# moonlight_application register map
Vendor: Nordic Semiconductor; Series: lumos; File version: 1
CPU: CM33 r0p4, little endian, MPU, FPU, 3 interrupt priority bits, 176 interrupts, 4 SAU regions
Registers are 32-bit, read-write, reset 0x0 unless marked. A register's access mark holds for its fields unless they carry their own. Offsets are from the block's base; [hi:lo] are bit positions; lines under a group give offsets from that group; 'fields as' and 'values as' point back to an identical list.

## GLOBAL_OSCILLATORS_NS — Oscillator control 0
Base 0x40120000
Same registers: GLOBAL_OSCILLATORS_S 0x50120000
0x700 XOSC32M group — 32 MHz oscillator control
  0x00 STATUS ro — Oscillator status
    [12:9] IDACFSMSTATE — Current IDAC Regulation State
      0=IDLE Mode; 1=ListenPkd (Listening for any changes on peak detector Mode); 2=WaitPkd (Waiting for peak detector to update Mode); 4=CodeIncrement (Incrementing IDAC Code Mode); 8=CodeDecrement (Decrementing IDAC Code Mode)
    [8:0] MAINFSMSTATE — Current Oscillator State
      6=Power Down Mode; 231=Standby Mode; 121=Pierce Mode; 0x139=ExtSin (External Sine Mode); 0x1AD=ExtSqrSin192M (External Square or Sine 192MHz Mode); 39=Power Up Mode; 37=PllCkStart (Pll Clock Started Mode); 45=PllCkRunningWaitCkRadio (Pll Clock Running And Waiting For Radio Clock Mode); 109=RadioCkStartWaitIdacRegulation (Radio Clock Started, Waiting For IDAC Regulation Mode); 105=RadioCkRunning (Radio Clock Running Mode); 0x127=PowerUpExtSin (Power Up to Sine External Mode); 0x1A7=PowerUpExtSqrSin192M (Power Up to Sine 192M, Square External Mode); 97=StandbyNoQuality (Standby With Both Clocks Started Mode); 103=StandbyClockMute (Standby to Start Both Clocks Mode); 0x1A5=ExtSqrSin192MNoQuality (External Sine 192M, Square With No Quality Signals Mode); 0x187=ExtSqrSin192MMute (External Sine 192M, Square With No Clocks Running Mode); 0x121=ExtSinNoQual (External Sine With No Quality Signals Mode); 0x107=ExtSinMute (External Sine With No Clocks Running Mode)
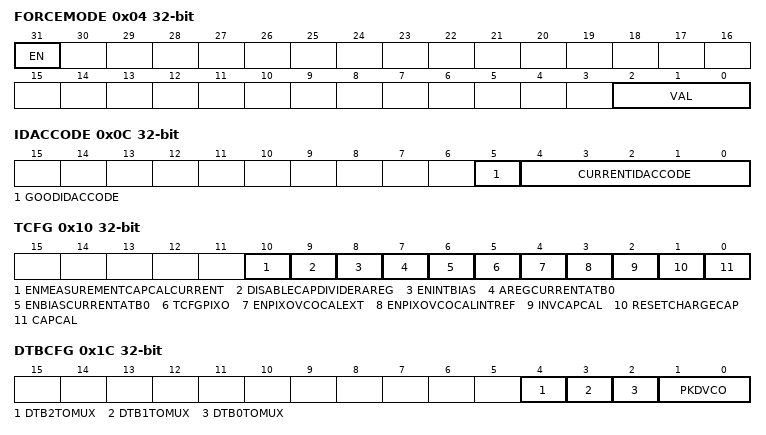
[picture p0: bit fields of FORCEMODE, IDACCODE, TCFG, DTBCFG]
  0x04 FORCEMODE — Force Xosc32M crystal into a certain mode
    [31] EN — Enable force mode for the XOSC32M
      0=Disabled (Disable force mode for FSM); 1=Enabled (Enable force mode for FSM)
    [2:0] VAL — Current Xosc32M mode
      0=PowerDown (Force to Power Down Mode); 1=Standby (Force to Standby mode); 2=Pierce (Force to Pierce mode); 3=ExtSqrSin192M (Force to External Square or External Sine 192MHz mode); 4=ExtSin (Force to External Sine mode)
  0x08 PEAKDETECTOR ro — Peak Detector pkdOut
    [2:0] PEAKDETECTOR — Current Peak Detector pkdOut
  0x0C IDACCODE ro — IDAC Regulation Code
    [5] GOODIDACCODE — The IDAC Regulation Took Place, and the Current IDAC Code is a Good Code
    [4:0] CURRENTIDACCODE — Current IDAC Regulation Code
  0x10 CLOCKQUALITY ro — Clock quality indicator
    [1:0] INDICATOR
      0=NoClockAvailable (XOSC32M does not output a clock); 1=PllQuality (XOSC32M outputs a clock that is used by PLL); 3=RadioQuality (XOSC32M has sufficient accuracy and the HFCLK controller has enabled the 32 MHz RADIO clock XOCLK32M)
  0x14 CONFIG group — Unspecified
    0x00 INJECTMODEENABLE — Enable injection mode for kickstarting the oscillator
      [0] VAL — Enable injection mode
        0=Disabled (Disable injection mode); 1=Enabled (Enable injection mode)
    0x04 FSMFREEZE — Freeze the FSM in the current mode (no inputs will change the FSM and this is used when requesting PIXO mode)
      [0] VAL — Enable FSM freeze
        0=Disabled (Disable FSM freeze); 1=Enabled (Enable FSM freeze)
    0x08 INTCAP reset 0x24 — Crystal load capacitor as seen by the crystal across its terminals, including pin capacitance but excluding PCB stray capacitance.
      [5:0] VAL
    0x0C UPDATEIDACCODE wo — Update IDAC code from APB (IDAC register).
      [0] UPDATE
        1=Trigger task
    0x10 TCFG — Test configuration bits
      [10] ENMEASUREMENTCAPCALCURRENT — Enable or disable measurement of 2 uA CAP_CAL current
        0=Disable measurement of 2 uA CAP_CAL current; 1=Enable measurement of 2 uA CAP_CAL current
      [9] DISABLECAPDIVIDERAREG — Enable or disable capacitive divider at AREG input when going to Pierce mode. This functionality will reduce start-up times in Pierce mode
        0=Enable capacitive divider at AREG; 1=Disable capacitive divider at AREG
      [8] ENINTBIAS — TCFG bit to enable bias (bias is normally only enabled when Pierce, SIN2SQR or PKD is enabled. This bit gives additional control of bias)
        0=Disable internal bias enabling; 1=Enable internal bias enabling
      [7] AREGCURRENTATB0 — Enable copy of AREG current to ATB0 (scaled down by x25)
        0=Disable copy of AREG current to ATB0; 1=Enable copy of AREG current to ATB0
      [6] ENBIASCURRENTATB0 — Enable 8 uA biasing current to ATB0 from internal biasing module
        0=Disable 8 uA biasing current; 1=Enable 8 uA biasing current
      [5] TCFGPIXO — Reserved or Spare TCFG Bit For PIXO
      [4] ENPIXOVCOCALEXT — Enable PIXO VCO Calibration Comparator From External Reference Voltage
        0=Disable PIXO VCO calibration comparator; 1=Enable PIXO VCO calibration comparator
      [3] ENPIXOVCOCALINTREF — Enable or disable PIXO VCO calibration comparator with internal reference voltage (resistive divider from VDD_ANA_0V9)
        values as ENPIXOVCOCALEXT
      [2] INVCAPCAL — Invert capacitor calibration comparator output
        0=No invert for capacitor calibration comparator output; 1=Invert capacitor calibration comparator output
      [1] RESETCHARGECAP — Reset charge on capacitor within capacitor calibration module
        0=Disable reset charge; 1=Enable (Reset charge on capacitor)
      [0] CAPCAL — Enable or disable capacitor calibration module
        0=Disable capacitor calibration module; 1=Enable capacitor calibration module
    0x14 ATB0CFG — Analog testbus 0 configuration
      [3:0] ATB0CFG
        0=HiZ0 (Allow other IPs to use ATB0); 1=HiZ1 (Allow other IPs to use ATB0); 7=HiZ2 (Allow other IPs to use ATB0); 8=IbppAtb8u (8 uA bias generator test current); 9=VcoCalCmp (Force external reference voltage to PIXO VCO calibration comparator (instead of using internal reference). This gives possibility to compare VCTRL of PIXO VCO with externally applied voltage); 10=IbppCapCal2u (2 uA current used for capacitor calibration); 11=IbppAregCpy (Copy of AREG current (divided down by x25))
    0x18 ATB1CFG — Analog testbus 1 configuration
      [3:0] ATB1CFG
        7=HiZ (Allow other IPs to use ATB1); 8=VddInt3V0 (Measure internal 3V0 voltage on ATB1); 11=Xosc32MPierce (Pierce clock on ATB1 for PN measurement in lab. Keep capacitance on ATB1 as low as possible for this measurement (maximum 30 pF)); 12=Xosc32MPixo (PIXO clock on ATB1 for PN measurement in lab. Keep capacitance on ATB1 as low as possible for this measurement (maximum 30 pF))
    0x1C DTBCFG — Digital Test Bus configuration
      [4] DTB2TOMUX — Connect DTB2 to internal MUX
      [3] DTB1TOMUX — Connect DTB1 to internal MUX
      [2] DTB0TOMUX — Connect DTB0 to internal MUX
      [1:0] PKDVCO
        0=Pkd123 (Monitoring of amplitude regulation process); 1=Xosc32MReady (Divided version of version of output clock and READY. Clock is divided down to 4 MHz internally); 2=PixoVcoComp (Output from PIXO VCO calibration comparator and output from capacitor calibration comparator); 3=READY, PKD_1 and PKD_2 on DTB makes it easier to measure start-up time in the lab since edge of READY can be used as reference start-point, while PKD outputs can be used as reference stop-points
  0x34 CALIBRATION group — Unspecified
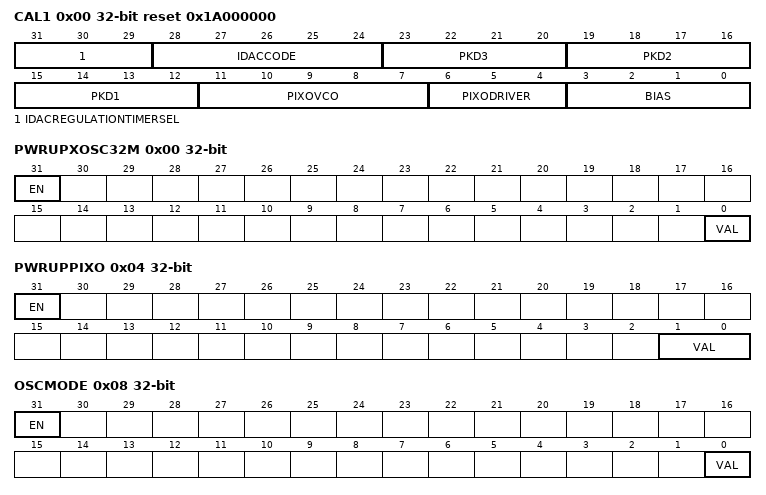
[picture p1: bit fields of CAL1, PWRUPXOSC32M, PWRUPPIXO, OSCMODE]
    0x00 CAL1 reset 0x1A000000 — Calibration registers written from FICR
      [31:29] IDACREGULATIONTIMERSEL — Configure the IDAC regulation time constant 256*(1 + n) us
      [28:24] IDACCODE — IDAC Configuration Value
      [23:20] PKD3 — Second complement trim bus for third peak detector
      [19:16] PKD2 — Second complement trim bus for second peak detector
      [15:12] PKD1 — Second complement trim bus for first peak detector
      [11:7] PIXOVCO — Second complement trim bus for PIXO VCO
      [6:4] PIXODRIVER — Second complement trim bus for PIXO drive strength
      [3:0] BIAS — Second complement trim bus for bias generator
  0x38 OVERRIDE group — Unspecified
    0x00 PWRUPXOSC32M — Override the PWRUP_XOSC32M signal in the analog module
      [31] EN — Enable the override
        0=Disabled (Override is disabled); 1=Enabled (Override is enabled)
      [0] VAL — Override value
    0x04 PWRUPPIXO — Override the XOSC32M_PIXO_PWRUP signal in the analog module
      [31] EN — Enable the override
        values as XOSC32M.OVERRIDE.PWRUPXOSC32M.EN
      [1:0] VAL — Override value
    0x08 OSCMODE — Override the XOSC32M_OSC_MODE signal in the analog module
      [31] EN — Enable the override
        values as XOSC32M.OVERRIDE.PWRUPXOSC32M.EN
      [0] VAL — Override value for the signal
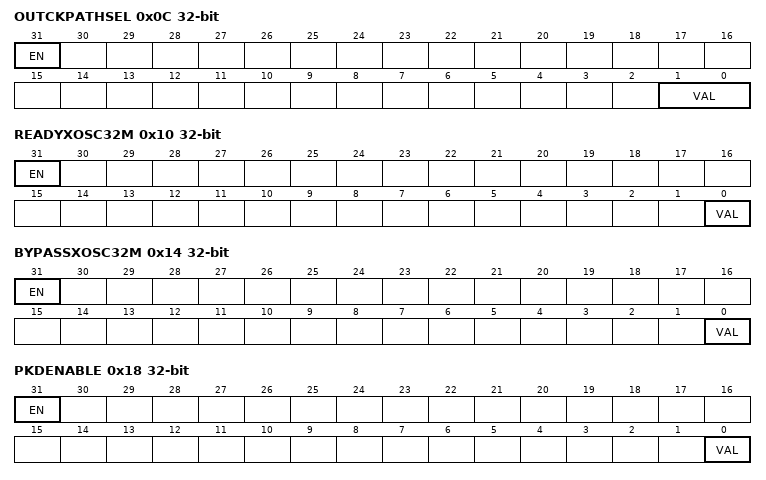
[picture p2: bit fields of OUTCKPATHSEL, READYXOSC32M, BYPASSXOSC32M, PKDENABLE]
    0x0C OUTCKPATHSEL — Override XOSC32M_OUTSEL signal in the analog module. 00: Sin-to-square output path (Pierce, ext-sin modes) 01: PIXO output path (PIXO mode) 10: Schmitt trigger output path (ext-sq mode) 11: Do not use
      [31] EN — Enable the override
        values as XOSC32M.OVERRIDE.PWRUPXOSC32M.EN
      [1:0] VAL — Override value for the signal
    0x10 READYXOSC32M — Override the READY_XOSC32M signal from analog module
      fields as XOSC32M.OVERRIDE.OSCMODE
    0x14 BYPASSXOSC32M — Override the XOSC32M_OSC_BYPASS signal in the analog module
      fields as XOSC32M.OVERRIDE.OSCMODE
    0x18 PKDENABLE — Override the XOSC32M_PKD_EN signal in the analog module
      fields as XOSC32M.OVERRIDE.OSCMODE
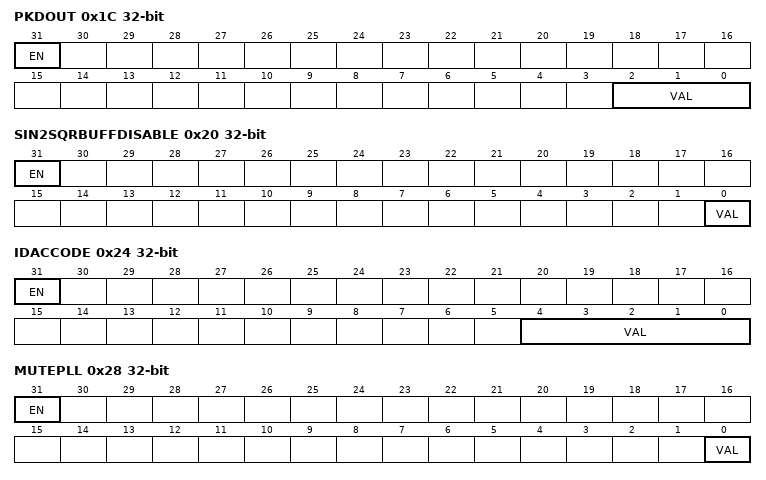
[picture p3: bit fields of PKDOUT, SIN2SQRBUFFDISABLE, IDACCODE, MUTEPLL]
    0x1C PKDOUT — Override the XOSC32M_PKD_OUT signal from analog module
      [31] EN — Enable the override
        values as XOSC32M.OVERRIDE.PWRUPXOSC32M.EN
      [2:0] VAL — Override value for the signal
    0x20 SIN2SQRBUFFDISABLE — Override the XOSC32M_SIN2SQR_DISABLE signal in the analog module
      fields as XOSC32M.OVERRIDE.OSCMODE
    0x24 IDACCODE — Override the XOSC32M_IDAC code in the analog module
      [31] EN — Enable the override
        values as XOSC32M.OVERRIDE.PWRUPXOSC32M.EN
      [4:0] VAL — Override value for the signal
    0x28 MUTEPLL — Override the XOSC32M_MUTE_PLL signal in the analog module
      [31] EN — Enable the override
        values as XOSC32M.OVERRIDE.PWRUPXOSC32M.EN
      [0] VAL — Override value of the signal
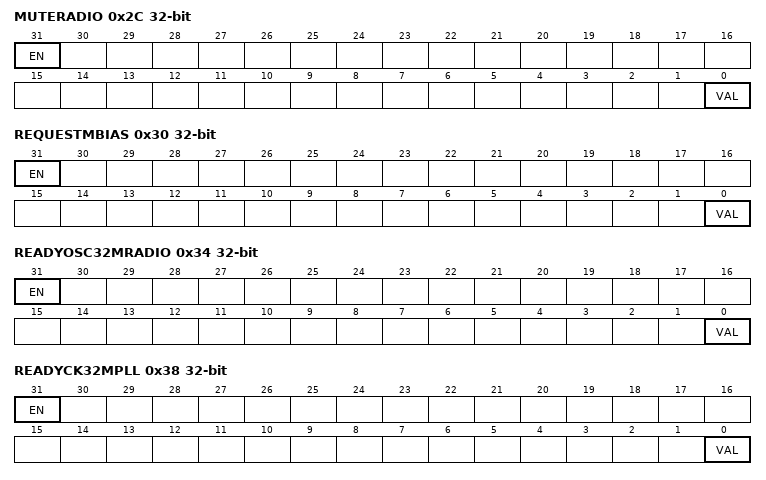
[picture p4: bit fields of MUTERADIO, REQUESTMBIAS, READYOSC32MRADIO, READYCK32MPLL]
    0x2C MUTERADIO — Override the XOSC32M_MUTE_RADIO signals in the analog module
      fields as XOSC32M.OVERRIDE.MUTEPLL
    0x30 REQUESTMBIAS — Override the requestMbias_a signal from the MMI
      fields as XOSC32M.OVERRIDE.MUTEPLL
    0x34 READYOSC32MRADIO — Override the readyOsc32M_Radio signals from the MMI
      fields as XOSC32M.OVERRIDE.MUTEPLL
    0x38 READYCK32MPLL — Override the readyCk32M_Pll signal from the MMI
      fields as XOSC32M.OVERRIDE.MUTEPLL
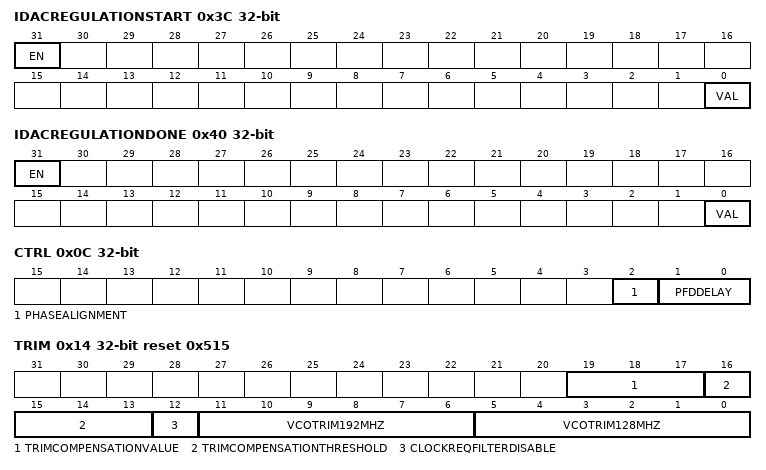
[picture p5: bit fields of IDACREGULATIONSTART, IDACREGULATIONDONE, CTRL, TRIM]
    0x3C IDACREGULATIONSTART — Override the idacRegulationStart signal from the main FSM
      fields as XOSC32M.OVERRIDE.MUTEPLL
    0x40 IDACREGULATIONDONE — Override the idacRegulationDone signal from the IDAC regulation FSM
      fields as XOSC32M.OVERRIDE.MUTEPLL
0x800 PLL group — Oscillator control
  0x00 FREQ reset 0x3 — CPU frequency
    [1:0] FREQ — Select CPU speed
      0=CK192M (192 MHz); 1=CK128M (128 MHz); 2=CK96M (96 MHz); 3=CK64M (64 MHz)
  0x04 CURRENTFREQ ro reset 0x3 — Current CPU frequency
    [1:0] CURRENTFREQ — Active CPU speed
      values as PLL.FREQ.FREQ
  0x10 CONFIG group — Unspecified
    0x00 ATB0CFG — Analog testbus configuration
      [1:0] ATB0CFG — Loop filter voltage and OSC_PLL_VHF_0V9
        0=Disabled; 1=VTUNE (Observe/force tune voltage VTUNE on ATB0); 2=OSC (Observe OSC_PLL_VHF_0V9 on ATB0)
    0x04 PROGCHPUMP — Program charge pump current
      [0] PROGCHPUMP
        0=I4uA (4 uA); 1=I8uA (8 uA)
    0x08 MUTE — Disable clock output
      [0] MUTE
        0=NotMuted (Clock is output); 1=Muted (Clock is not output)
    0x0C CTRL — PLL control register
      [2] PHASEALIGNMENT — Disables phase alignment at startup, and enables PFD in calibration mode
      [1:0] PFDDELAY — Adjust internal PFD delay / CP minimum UP/DN pulse length
        0=P0 (Minimum delay); 1=P50 (+50 ps delay); 2=P100 (+100 ps delay); 3=P150 (+150 ps delay)
    0x10 TEST — Unspecified
      [5:0] TEST — PLL_TEST_0V9[5]: Override hardcoded bias setup for VCO. PLL_TEST_0V9[4:3]: KVCO controlling bias. PLL_TEST_0V9[2:0]: constant current controlling bias.
    0x14 TRIM reset 0x515 — VCO trim values for the 192 MHz PLL
      [19:17] TRIMCOMPENSATIONVALUE — Trim compensation when deviation larger than TRIMCOMPENSATIONTHRESHOLD is detected.
        0=Disabled (Trim compensation disabled); 1=T1 (Compensate with 1 trim step (~1.5 percent)); 7=T7 (Compensate with 7 trim step (~10.5 percent))
      [16:13] TRIMCOMPENSATIONTHRESHOLD — Threshold for enabling trim compenastion. Trim compensation actived when measured cycles are below the threshold.
        0=T132 (Threshold at 132 cycles (~0.75 percent)); 1=T131 (Threshold at 131 cycles (~1.5 percent)); 15=T117 (Threshold at 117 cycles (~12 percent))
      [12] CLOCKREQFILTERDISABLE — Disable clock request filter
        0=Enable clock request filter; 1=Disable clock request filter
      [11:6] VCOTRIM192MHZ — Trim value for the PLL VCO at 192 MHz
      [5:0] VCOTRIM128MHZ — Trim value for the PLL VCO at 128 MHz
  0x30 DBG group — Unspecified
    0x00 STATUS ro — Current state of the MMIs state machine
      [7:0] STATE — Current state of the MMI state machine
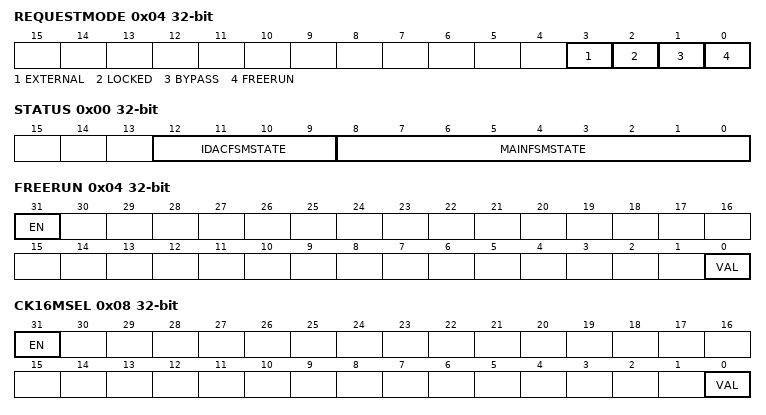
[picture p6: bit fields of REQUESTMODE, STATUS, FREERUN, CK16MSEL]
    0x04 REQUESTMODE — Backdoor to request PLL mode
      [3] EXTERNAL — Request external mode
        0=Disabled (No request); 1=Request external mode
      [2] LOCKED — Request locked mode
        0=Disabled (No request); 1=Request locked mode
      [1] BYPASS — Request bypass mode
        0=Disabled (No request); 1=Request bypass mode
      [0] FREERUN — Request free running mode
        0=Disabled (No request); 1=Request free running mode
  0x40 FREQMETER group — Unspecified
    0x00 STATUS ro — Status of frequency meter
      [16] STATUS — Status of frequency meter
        0=Idle (Frequency meter idle.); 1=Ongoing (Frequency measurement ongoing.)
      [10:0] RESULT — Result from last frequency measurement (HF cycles).
    0x04 START wo — Start a new frequency measurement.
      [0] START — Input clock for calibration engine.
        1=Trigger task
    0x08 CONFIG — Frequency meter config
      [0] MODE — Sets frequency meter mode.
        0=Locktuning (Target 132 HF cycles.); 1=Calibration (Measure for 8 us.)
  0x50 CAL group — Unspecified
    0x00 ENABLE — Enable ring oscillator calibration
      [0] CALENABLE
        0=Disable (Normal operation); 1=Enabled (Calibration mode)
    0x04 CLK — Input clock for calibration engine. Not used in normal operation
      [0] CALCLK — Input clock for calibration engine
    0x08 CMP ro — Ring oscillator calibration comparator output
      [0] CALCMP
  0x60 OVERRIDE group — Unspecified
    0x00 PWRUP — Override PWRUP
      [31] EN — Enable override
        values as XOSC32M.OVERRIDE.PWRUPXOSC32M.EN
      [0] VAL — Override value
    0x04 FREERUN — Override FREERUN
      fields as PLL.OVERRIDE.PWRUP
    0x08 CK16MSEL — Override CK16M_SEL
      [31] EN — Enable override
        values as XOSC32M.OVERRIDE.PWRUPXOSC32M.EN
      [0] VAL — Override value
        0=Bypass 32M outputs from reference; 1=Normal (32M generated internally)
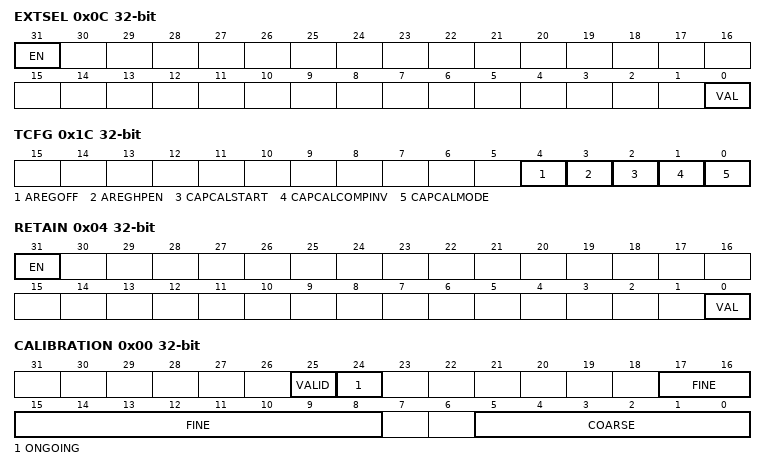
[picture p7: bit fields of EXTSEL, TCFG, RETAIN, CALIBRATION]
    0x0C EXTSEL — Override EXT_SEL
      [31] EN — Enable override
        values as XOSC32M.OVERRIDE.PWRUPXOSC32M.EN
      [0] VAL — Override value
        0=Normal operation; 1=External (Reference clock bypassed to VCO output. Internal dividers functional)
    0x10 FREQ — Override frequency handler. Value directly from FREQ register
      [31] EN — Enable override
        values as XOSC32M.OVERRIDE.PWRUPXOSC32M.EN
0x900 XOSC32KI group — 32 kHz oscillator control
  0x00 BYPASS — Enable or disable bypass of LFCLK crystal oscillator with external clock source
    [0] BYPASS
      0=Disabled (Disable (use with crystal or low-swing external source)); 1=Enabled (Enable (use with rail-to-rail external source))
  0x04 INTCAP — Programmable capacitance of XC1 and XC2
    [5:0] VAL — Crystal load capacitor as seen by the crystal across its terminals, including pin capacitance but excluding PCB stray capacitance.
  0x08 TRIM — Trim values
    [4] EXTBIAS — Control the use of external bias current
      0=Disabled (Internal bias current is used); 1=Enabled (External bias current is used)
    [3:0] CONSTCURRTRIM — Constant current level trim. 0 - 90 nA in 6 nA step size (typical)
  0x0C MUTE — Disable clock output
    [0] MUTE
      0=NotMuted (Clock output on OSC_32K_0V9); 1=Muted (Clock is muted. OSC_32K_0V9 is zero.)
  0x10 PDCORE — Power down crystal driver
    [0] POWERDOWN
      0=PowerUp (Pierce cell, amplitude regulator, and IDAC are powered.); 1=PowerDown (Pierce cell, amplitude regulator, and IDAC are powered down.)
  0x14 ATBCFG — Analog testbus configuration
    [1:0] ATBCFG — Analog testbus control
      0=Disabled; 2=IntBias (Internal bias to ATB0)
  0x18 DTBCFG — Digital testbus configuration
    [1:0] DTBCFG — Digital testbus control
      0=Vss; 2=CmpCapCal
  0x1C TCFG — Test configuration bus
    [4] AREGOFF — AREG off, only constant current source driving xtal
      0=AregOn (Unspecified); 1=AregOff (Unspecified)
    [3] AREGHPEN — Enable AREG_HP mode, 2x current in AREG
      0=Disabled (Unspecified); 1=Enabled (Unspecified)
    [2] CAPCALSTART — Start CAPCAL measurement
      0=DoNotStart (Unspecified); 1=Start (Unspecified)
    [1] CAPCALCOMPINV — Invert CAPCAL comparators
      0=NotInverted (Unspecified); 1=Inverted (Unspecified)
    [0] CAPCALMODE — CAPCAL mode enable
      0=Disabled (Unspecified); 1=Enabled (Unspecified)
  0x20 OVERRIDE group — Unspecified
    0x00 PWRUP — Override PWRUP
      fields as PLL.OVERRIDE.PWRUP
    0x04 RETAIN — Override RETAIN
      fields as PLL.OVERRIDE.PWRUP
0xA00 RCOSC32K group — 32.768 kHz RC oscillator
  0x00 CALIBRATION ro — Calibration status
    [25] VALID — Calibration has been completed
      0=NoValid (Calibration is not ongoing); 1=Calid (Calibration is ongoing)
    [24] ONGOING — Calibration is ongoing
      0=Idle (Calibration is not ongoing); 1=Ongoing (Calibration is ongoing)
    [17:8] FINE — Fine calibration value
    [5:0] COARSE — Coarse calibration value
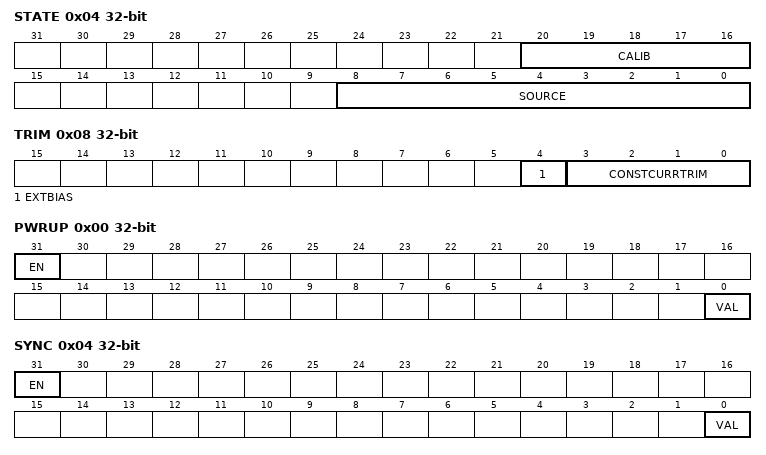
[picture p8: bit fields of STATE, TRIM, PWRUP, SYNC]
  0x04 STATE ro — FSM states
    [20:16] CALIB — Calibration engine state
      0=RESET (Unspecified); 1=SETTLING (Unspecified); 2=INIT_MEAS_FAST (Unspecified); 3=MEAS_FAST (Unspecified); 4=INIT_MEAS_SLOW (Unspecified); 5=MEAS_SLOW (Unspecified); 22=PROG_COARSE (Unspecified); 15=PROG_FINE (Unspecified); 24=IDLE (Unspecified)
    [8:0] SOURCE — Source controller FSM state
      91=STANDBY (Unspecified); 31=ENABLE_DEBOUNCER (Unspecified); 15=START_XOSC (Unspecified); 0x123=START_CALIB (Unspecified); 133=CALIB (Unspecified); 39=SYNC_RCOSC (Unspecified); 13=SWITCH_OSC (Unspecified); 11=STOP_XOSC (Unspecified); 27=NORMAL_MODE (Unspecified); 38=SYNC_RCOSC_PWR_DOWN (Unspecified); 12=SWITCH_OSC_PWR_DOWN (Unspecified); 10=STOP_XOSC_PWR_DOWN (Unspecified); 25=STOP_RCOSC_PWR_DOWN (Unspecified)
  0x08 TRIM — RCOSC coarse calibration input This value is read from FICR
    [7:2] TRIMCOARSEIN — RCOSC coarse calibration input
    [1:0] CALLENGTH — 32kHz RC oscillator calibration length in number of cycles
      0=N64 (64 cycles); 1=N128 (128 cycles); 2=N256 (256 cycles); 3=N512 (512 cycles)
  0x0C ATBCFG — Analog testbus configuration
    [0] ATBCFG — Enable analog test bus 0
      0=Disabled; 1=Enabled (Connect output from built-in voltage regulator to ATB0)
  0x10 DTBCFG — Digital testbus configuration
    [0] DTBCFG — Enable digital test bus out 0
      0=Disabled; 1=Enabled (OSC_RC32K on DTBO0)
  0x14 TCFG — Test configuration
    [1:0] TCFG
      0=NormalMode; 1=IncreaseCurrent (Increase comparator tail current by a factor of two); 2=DisableCmp (Disable adaptive biasing of comparator); 3=Illegal
  0x18 MUTE — Mute clock output
    [0] MUTE — Test configuration
      0=Disabled (Normal operation); 1=Enabled (Enable clock muting)
  0x1C DISABLERCOSC32KIPOWERUPCONTROL — Backdoor for disabling Rcosc32KiPowerUpControl module in Rcosc32KiGenerator
    [0] Disable — Disable Rcosc32KiPowerUpControl.
      0=Enabled (Rcosc32KiPowerUpControl is enabled); 1=Disabled (Rcosc32KiPowerUpControl is disabled)
  0x20 OVERRIDE group — Unspecified
    0x00 PWRUP — Override PWRUP
      fields as PLL.OVERRIDE.PWRUP
    0x04 SYNC — Override SYNC
      fields as PLL.OVERRIDE.PWRUP
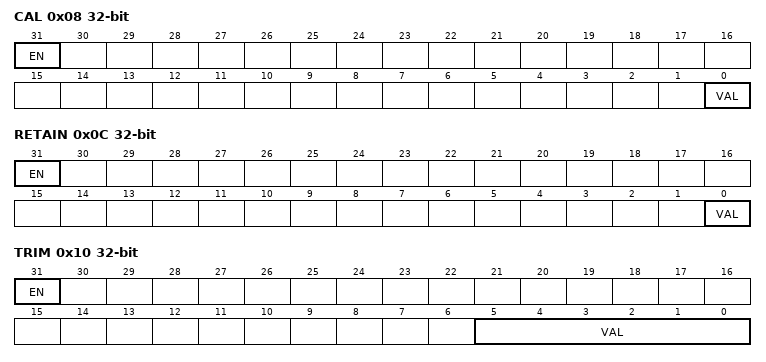
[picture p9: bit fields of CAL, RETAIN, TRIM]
    0x08 CAL — Override CAL
      fields as PLL.OVERRIDE.PWRUP
    0x0C RETAIN — Override RETAIN
      fields as PLL.OVERRIDE.PWRUP
    0x10 TRIM — Override TRIM
      [31] EN — Enable override
        values as XOSC32M.OVERRIDE.PWRUPXOSC32M.EN
      [5:0] VAL — Override value
